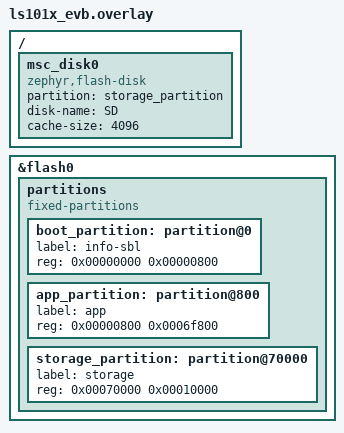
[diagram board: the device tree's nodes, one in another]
/*
 * Copyright (c) 2023 Nordic Semiconductor ASA
 *
 * SPDX-License-Identifier: Apache-2.0
 */

/* Because FAT FS needs at least 64kiB partition and default
 * storage_partition is 32kiB for that board, we need to reorgatnize
 * partitions to get at least 64KiB.
 * This overlay removes image slot partitions and strips each of 64kiB,
 * and removes the storage partition to add the additional 2*64kiB to
 * it.
 */
/delete-node/ &boot_partition;
/delete-node/ &app_partition;
/delete-node/ &storage_partition;

&flash0 {

    /*
	* Flash base address is 0x8000000,
    * the following parts are all offset addresses.
	*/

	partitions {
		compatible = "fixed-partitions";
		#address-cells = <1>;
		#size-cells = <1>;

		boot_partition: partition@0 {
			label = "info-sbl";
			reg = <0x00000000 0x00000800>;
		};
	
        app_partition: partition@800 {
			label = "app";
			reg = <0x00000800 0x0006f800>;
		};

		/*
		 * The flash starting at 0x807d000 and ending at
		 * 0x807FFFF is reserved for use by the application.
		 */

		/*
		 * Storage partition will be used by FCB/LittleFS/NVS
		 * if enabled.
		 */
		storage_partition: partition@70000 {
			label = "storage";
			reg = <0x00070000 0x00010000>;
		};
	};
};

/ {
	msc_disk0 {
		status="okay";
		compatible = "zephyr,flash-disk";
		partition = <&storage_partition>;
		disk-name = "SD";
		/* cache-size == page erase size */
		cache-size = <4096>;
	};
};
